# XMC4300 register map
Vendor: Infineon; File version: 1.0.4 (Reference Manual v1.0)
CPU: CM4 r2p0, little endian, MPU, FPU, 6 interrupt priority bits
Registers are 32-bit, read-write, reset 0x0 unless marked. A register's access mark holds for its fields unless they carry their own. Offsets are from the block's base; [hi:lo] are bit positions; 'fields as' and 'values as' point back to an identical list.

## SCU_PLL — System Control Unit
Base 0x50004710
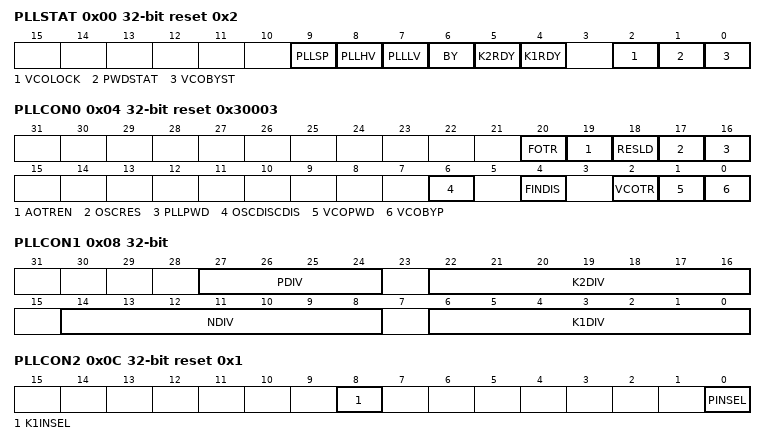
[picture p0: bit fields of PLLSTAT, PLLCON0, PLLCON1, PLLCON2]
0x00 PLLSTAT ro reset 0x2 — PLL Status Register
  [9] PLLSP — Oscillator for PLL Valid Spike Status Bit
    0=Const_0 (The OSC frequency is not usable. Spikes are detected that disturb a locked operation); 1=Const_1 (The OSC frequency is usable)
  [8] PLLHV — Oscillator for PLL Valid High Status Bit
    0=Const_0 (The OSC frequency is not usable. Frequency fOSC is too high.); 1=Const_1 (The OSC frequency is usable)
  [7] PLLLV — Oscillator for PLL Valid Low Status Bit
    0=Const_0 (The OSC frequency is not usable. Frequency fREF is too low.); 1=Const_1 (The OSC frequency is usable)
  [6] BY — Bypass Mode Status
    0=Const_0 (Bypass Mode is not entered); 1=Const_1 (Bypass Mode is entered. Input fOSC is selected as output fPLL.)
  [5] K2RDY — K2 Divider Ready Status
    0=Const_0 (K2-Divider does not operate with the new value); 1=Const_1 (K2-Divider operate with the new value)
  [4] K1RDY — K1 Divider Ready Status
    0=Const_0 (K1-Divider does not operate with the new value); 1=Const_1 (K1-Divider operate with the new value)
  [2] VCOLOCK — PLL LOCK Status
    0=Const_0 (PLL not locked); 1=Const_1 (PLL locked)
  [1] PWDSTAT — PLL Power-saving Mode Status
    0=Const_0 (PLL Power-saving Mode was not entered); 1=Const_1 (PLL Power-saving Mode was entered)
  [0] VCOBYST — VCO Bypass Status
    0=Const_0 (Free-running / Normal Mode is entered); 1=Const_1 (Prescaler Mode is entered)
0x04 PLLCON0 access per field reset 0x30003 — PLL Configuration 0 Register
  [20] FOTR rw — Factory Oscillator Calibration
    0=Const_0 (No effect); 1=Const_1 (Force fixed-value trimming)
  [19] AOTREN rw — Automatic Oscillator Calibration Enable
    0=Const_0 (Disable); 1=Const_1 (Enable)
  [18] RESLD wo — Restart VCO Lock Detection
  [17] OSCRES rw — Oscillator Watchdog Reset
    0=Const_0 (The Oscillator Watchdog of the PLL is not reset and remains active); 1=Const_1 (The Oscillator Watchdog of the PLL is reset)
  [16] PLLPWD rw — PLL Power Saving Mode
    0=Const_0 (Normal behavior); 1=Const_1 (The complete PLL block is put into a Power Saving Mode and can no longer be used. Only the Bypass Mode is active if previously selected.)
  [6] OSCDISCDIS rw — Oscillator Disconnect Disable
    0=Const_0 (In case of a PLL loss-of-lock bit FINDIS is set); 1=Const_1 (In case of a PLL loss-of-lock bit FINDIS is cleared)
  [4] FINDIS rw — Disconnect Oscillator from VCO
    0=Const_0 (connect oscillator to the VCO part); 1=Const_1 (disconnect oscillator from the VCO part.)
  [2] VCOTR rw — VCO Trim Control
    0=Const_0 (VCO bandwidth is operation in the normal range. VCO output frequency is between 260 and 520 MHz for a input frequency between 8 and 16 MHz.); 1=Const_1 (VCO bandwidth is operation in the test range. VCO output frequency is between 260 and 520 MHz for a input frequency between 8 and 16 MHz.)
  [1] VCOPWD rw — VCO Power Saving Mode
    0=Const_0 (Normal behavior); 1=Const_1 (The VCO is put into a Power Saving Mode and can no longer be used. Only the Bypass and Prescaler Mode are active if previously selected.)
  [0] VCOBYP rw — VCO Bypass
    0=Const_0 (Normal operation, VCO is not bypassed); 1=Const_1 (Prescaler Mode, VCO is bypassed)
0x08 PLLCON1 — PLL Configuration 1 Register
  [27:24] PDIV — P-Divider Value
  [22:16] K2DIV — K2-Divider Value
  [14:8] NDIV — N-Divider Value
  [6:0] K1DIV — K1-Divider Value
0x0C PLLCON2 reset 0x1 — PLL Configuration 2 Register
  [8] K1INSEL — K1-Divider Input Selection
    0=Const_0 (PLL external oscillator selected); 1=Const_1 (Backup clock fofi selected)
  [0] PINSEL — P-Divider Input Selection
    values as K1INSEL
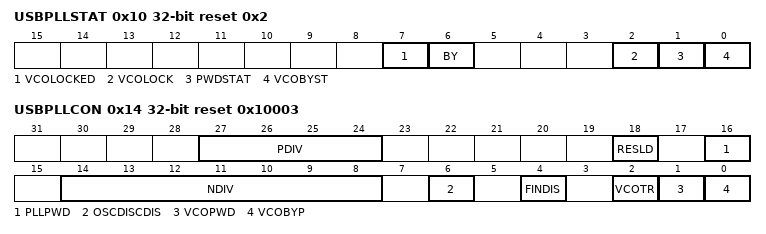
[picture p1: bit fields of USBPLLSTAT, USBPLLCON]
0x10 USBPLLSTAT ro reset 0x2 — USB PLL Status Register
  [7] VCOLOCKED — PLL LOCK Status
    0=Const_0 (PLL not locked); 1=Const_1 (PLL locked)
  [6] BY — Bypass Mode Status
    values as PLLSTAT.BY
  [2] VCOLOCK — PLL VCO Lock Status
    0=Const_0 (The frequency difference of fREF and fDIV is greater than allowed. The VCO part of the PLL can not lock on a target frequency.); 1=Const_1 (The frequency difference of fREF and fDIV is small enough to enable a stable VCO operation)
  [1] PWDSTAT — PLL Power-saving Mode Status
    values as PLLSTAT.PWDSTAT
  [0] VCOBYST — VCO Bypass Status
    0=Const_0 (Normal Mode is entered); 1=Const_1 (Prescaler Mode is entered)
0x14 USBPLLCON access per field reset 0x10003 — USB PLL Configuration Register
  [27:24] PDIV rw — P-Divider Value
  [18] RESLD wo — Restart VCO Lock Detection
  [16] PLLPWD rw — PLL Power Saving Mode
    0=Const_0 (Normal behavior); 1=Const_1 (The complete PLL block is put into a Power Saving Mode. Only the Bypass Mode is active if previously selected.)
  [14:8] NDIV rw — N-Divider Value
  [6] OSCDISCDIS rw — Oscillator Disconnect Disable
    values as PLLCON0.OSCDISCDIS
  [4] FINDIS rw — Disconnect Oscillator from VCO
    0=Const_0 (Connect oscillator to the VCO part); 1=Const_1 (Disconnect oscillator from the VCO part.)
  [2] VCOTR rw — VCO Trim Control
    0=Const_0 (VCO bandwidth is operating in the normal range. VCO output frequency is between 260 and 520 MHz for a input frequency between 8 and 16 MHz.); 1=Const_1 (VCO bandwidth is operating in the test range. VCO output frequency is between 260 and 520 MHz for a input frequency between 8 and 16 MHz.)
  [1] VCOPWD rw — VCO Power Saving Mode
    0=Const_0 (Normal behavior); 1=Const_1 (The VCO is put into a Power Saving Mode)
  [0] VCOBYP rw — VCO Bypass
    values as PLLCON0.VCOBYP
0x28 CLKMXSTAT ro — Clock Multiplexing Status Register
  [1:0] SYSCLKMUX — Status of System Clock Multiplexing Upon Source Switching
    1=Const_x1 (fOFI clock active); 2=Const_1x (fPLL clock active)
